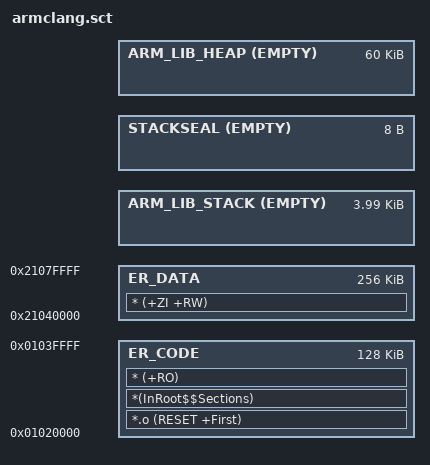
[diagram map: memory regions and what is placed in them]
#! armclang --target=arm-arm-none-eabi -march=armv8.1-m.main+mve.fp+fp.dp -E -x c
/*
 * Copyright (c) 2021-2024 Arm Limited. All rights reserved.
 *
 * Licensed under the Apache License, Version 2.0 (the "License");
 * you may not use this file except in compliance with the License.
 * You may obtain a copy of the License at
 *
 *     http://www.apache.org/licenses/LICENSE-2.0
 *
 * Unless required by applicable law or agreed to in writing, software
 * distributed under the License is distributed on an "AS IS" BASIS,
 * WITHOUT WARRANTIES OR CONDITIONS OF ANY KIND, either express or implied.
 * See the License for the specific language governing permissions and
 * limitations under the License.
 */

#define NS_ROM_START            0x01020000
#define NS_ROM_SIZE             0x00020000
#define NS_RAM_START            0x21040000
#define NS_RAM_SIZE             0x00040000
#define STACK_SIZE              0x00001000
#define HEAP_SIZE               0x0000F000
#define __STACKSEAL_SIZE        0x8

LOAD_REGION_0 NS_ROM_START NS_ROM_SIZE
{
    ER_CODE NS_ROM_START NS_ROM_SIZE {
        *.o (RESET +First)
        *(InRoot$$Sections)
        * (+RO)
    }

    ER_DATA NS_RAM_START NS_RAM_SIZE {
        * (+ZI +RW)
    }

    ARM_LIB_STACK +0 ALIGN 32 EMPTY STACK_SIZE - __STACKSEAL_SIZE {
    }

    STACKSEAL +0 EMPTY __STACKSEAL_SIZE {
    }

    ARM_LIB_HEAP +0 ALIGN 8 EMPTY HEAP_SIZE {
    }
}
